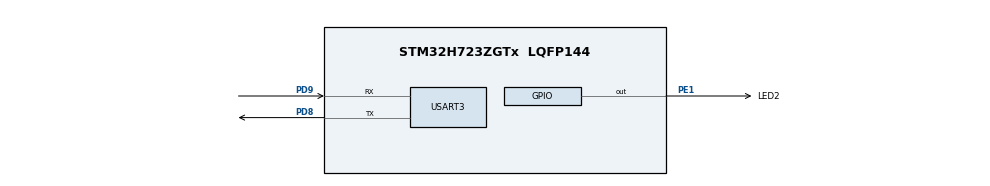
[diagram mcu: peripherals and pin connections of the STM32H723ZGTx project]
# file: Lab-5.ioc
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ADC3.Channel-0\#ChannelRegularConversion=ADC_CHANNEL_TEMPSENSOR
ADC3.NbrOfConversionFlag=1
ADC3.OffsetNumber-0\#ChannelRegularConversion=ADC_OFFSET_NONE
ADC3.OffsetSign-0\#ChannelRegularConversion=ADC3_OFFSET_SIGN_NEGATIVE
ADC3.Rank-0\#ChannelRegularConversion=1
ADC3.SamplingTime-0\#ChannelRegularConversion=ADC3_SAMPLETIME_2CYCLES_5
CORTEX_M7.default_mode_Activation=1
Mcu.Family=STM32H7
Mcu.Name=STM32H723ZGTx
Mcu.Package=LQFP144
NVIC.PriorityGroup=NVIC_PRIORITYGROUP_4
PA13(JTMS/SWDIO).Signal=DEBUG_JTMS-SWDIO
PA14(JTCK/SWCLK).Signal=DEBUG_JTCK-SWCLK
PC14-OSC32_IN.Mode=LSE-External-Oscillator
PC14-OSC32_IN.Signal=RCC_OSC32_IN
PC15-OSC32_OUT.Mode=LSE-External-Oscillator
PC15-OSC32_OUT.Signal=RCC_OSC32_OUT
PD8.Mode=Asynchronous
PD8.Signal=USART3_TX
PD9.Mode=Asynchronous
PD9.Signal=USART3_RX
PE1.GPIO_Label=LED2
PE1.Signal=GPIO_Output
ProjectManager.HeapSize=0x200
ProjectManager.StackSize=0x400
ProjectManager.TargetToolchain=Makefile
RCC.ADCFreq_Value=38400000
RCC.APB1Freq_Value=32000000
RCC.APB2Freq_Value=64000000
RCC.APB3Freq_Value=64000000
RCC.APB4Freq_Value=64000000
RCC.CortexFreq_Value=64000000
RCC.D2PPRE1=RCC_APB1_DIV2
RCC.DIVM2=4
RCC.DIVN2=12
RCC.DIVP2=5
RCC.HCLKFreq_Value=64000000
RCC.PLL2FRACN=0
RCC.SYSCLKFreq_VALUE=64000000
RCC.USBFreq_Value=129000000
USART3.VirtualMode-Asynchronous=VM_ASYNC
VP_ADC3_TempSens_Input.Mode=IN-TempSens
VP_MEMORYMAP_VS_MEMORYMAP.Mode=CurAppReg
board=custom

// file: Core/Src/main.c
/* USER CODE BEGIN Header */
/**
  ******************************************************************************
  * @file           : main.c
  * @brief          : Main program body
  ******************************************************************************
  * @attention
  *
  * Copyright (c) 2025 STMicroelectronics.
  * All rights reserved.
  *
  * This software is licensed under terms that can be found in the LICENSE file
  * in the root directory of this software component.
  * If no LICENSE file comes with this software, it is provided AS-IS.
  *
  ******************************************************************************
  */
/* USER CODE END Header */
#include "main.h"

/* USER CODE BEGIN Includes */
#include <string.h>

/* USER CODE END Includes */

/* USER CODE BEGIN PD */
#define ADC_BUFF_LEN 4096

/* USER CODE END PD */

ADC_HandleTypeDef hadc3;

UART_HandleTypeDef huart3;

void SystemClock_Config(void);
static void MPU_Config(void);
static void MX_GPIO_Init(void);
static void MX_USART3_UART_Init(void);
static void MX_ADC3_Init(void);

/* USER CODE BEGIN 0 */
char buffer[100];
void _LOG_write_raw(char *txt);
uint16_t adc_buff[ADC_BUFF_LEN];

uint16_t get_ADC(){

  HAL_ADC_Start(&hadc3);
  HAL_ADC_PollForConversion(&hadc3, 1000);
  uint16_t value = HAL_ADC_GetValue(&hadc3);

  HAL_ADC_Stop(&hadc3);

  return value;
}

float convert_temp(uint16_t d_adc){

  float v_adc = d_adc * (3.3 / 4095.0);
  float temp = ((v_adc - 0.78 / 2.5));

  return temp;
}

/* USER CODE END 0 */

int main(void)
{

  /* MPU Configuration--------------------------------------------------------*/
  MPU_Config();

  /* MCU Configuration--------------------------------------------------------*/

  /* Reset of all peripherals, Initializes the Flash interface and the Systick. */
  HAL_Init();

  /* Configure the system clock */
  SystemClock_Config();

  /* Initialize all configured peripherals */
  MX_GPIO_Init();
  MX_USART3_UART_Init();
  MX_ADC3_Init();
  /* USER CODE BEGIN 2 */

  uint32_t t0;
  t0 = HAL_GetTick();
  uint16_t temp_adc = 0;

  /* USER CODE END 2 */

  /* Infinite loop */
  while (1)
  {
    if(HAL_GetTick() - t0 > 5000){

      uint16_t tmp = get_ADC();
      temp_adc = convert_temp(tmp);

      snprintf(buffer, sizeof(buffer), "Temperatire: %hu")
      _LOG_write_raw(buffer);
      t0 = HAL_GetTick();
    }

  }
}

void SystemClock_Config(void)
{
  RCC_OscInitTypeDef RCC_OscInitStruct = {0};
  RCC_ClkInitTypeDef RCC_ClkInitStruct = {0};

  /** Supply configuration update enable
  */
  HAL_PWREx_ConfigSupply(PWR_LDO_SUPPLY);

  /** Configure the main internal regulator output voltage
  */
  __HAL_PWR_VOLTAGESCALING_CONFIG(PWR_REGULATOR_VOLTAGE_SCALE3);

  while(!__HAL_PWR_GET_FLAG(PWR_FLAG_VOSRDY)) {}

  /** Macro to configure the PLL clock source
  */
  __HAL_RCC_PLL_PLLSOURCE_CONFIG(RCC_PLLSOURCE_HSI);

  /** Initializes the RCC Oscillators according to the specified parameters
  * in the RCC_OscInitTypeDef structure.
  */
  RCC_OscInitStruct.OscillatorType = RCC_OSCILLATORTYPE_HSI;
  RCC_OscInitStruct.HSIState = RCC_HSI_DIV1;
  RCC_OscInitStruct.HSICalibrationValue = 64;
  RCC_OscInitStruct.PLL.PLLState = RCC_PLL_NONE;
  if (HAL_RCC_OscConfig(&RCC_OscInitStruct) != HAL_OK)
  {
    Error_Handler();
  }

  /** Initializes the CPU, AHB and APB buses clocks
  */
  RCC_ClkInitStruct.ClockType = RCC_CLOCKTYPE_HCLK|RCC_CLOCKTYPE_SYSCLK
                              |RCC_CLOCKTYPE_PCLK1|RCC_CLOCKTYPE_PCLK2
                              |RCC_CLOCKTYPE_D3PCLK1|RCC_CLOCKTYPE_D1PCLK1;
  RCC_ClkInitStruct.SYSCLKSource = RCC_SYSCLKSOURCE_HSI;
  RCC_ClkInitStruct.SYSCLKDivider = RCC_SYSCLK_DIV1;
  RCC_ClkInitStruct.AHBCLKDivider = RCC_HCLK_DIV1;
  RCC_ClkInitStruct.APB3CLKDivider = RCC_APB3_DIV1;
  RCC_ClkInitStruct.APB1CLKDivider = RCC_APB1_DIV2;
  RCC_ClkInitStruct.APB2CLKDivider = RCC_APB2_DIV1;
  RCC_ClkInitStruct.APB4CLKDivider = RCC_APB4_DIV1;

  if (HAL_RCC_ClockConfig(&RCC_ClkInitStruct, FLASH_LATENCY_1) != HAL_OK)
  {
    Error_Handler();
  }
}

static void MX_ADC3_Init(void)
{

  ADC_ChannelConfTypeDef sConfig = {0};

  /** Common config
  */
  hadc3.Instance = ADC3;
  hadc3.Init.ClockPrescaler = ADC_CLOCK_ASYNC_DIV1;
  hadc3.Init.Resolution = ADC_RESOLUTION_12B;
  hadc3.Init.DataAlign = ADC3_DATAALIGN_RIGHT;
  hadc3.Init.ScanConvMode = ADC_SCAN_DISABLE;
  hadc3.Init.EOCSelection = ADC_EOC_SINGLE_CONV;
  hadc3.Init.LowPowerAutoWait = DISABLE;
  hadc3.Init.ContinuousConvMode = DISABLE;
  hadc3.Init.NbrOfConversion = 1;
  hadc3.Init.DiscontinuousConvMode = DISABLE;
  hadc3.Init.ExternalTrigConv = ADC_SOFTWARE_START;
  hadc3.Init.ExternalTrigConvEdge = ADC_EXTERNALTRIGCONVEDGE_NONE;
  hadc3.Init.DMAContinuousRequests = DISABLE;
  hadc3.Init.SamplingMode = ADC_SAMPLING_MODE_NORMAL;
  hadc3.Init.ConversionDataManagement = ADC_CONVERSIONDATA_DR;
  hadc3.Init.Overrun = ADC_OVR_DATA_PRESERVED;
  hadc3.Init.LeftBitShift = ADC_LEFTBITSHIFT_NONE;
  hadc3.Init.OversamplingMode = DISABLE;
  hadc3.Init.Oversampling.Ratio = ADC3_OVERSAMPLING_RATIO_2;
  if (HAL_ADC_Init(&hadc3) != HAL_OK)
  {
    Error_Handler();
  }

  /** Configure Regular Channel
  */
  sConfig.Channel = ADC_CHANNEL_TEMPSENSOR;
  sConfig.Rank = ADC_REGULAR_RANK_1;
  sConfig.SamplingTime = ADC3_SAMPLETIME_2CYCLES_5;
  sConfig.SingleDiff = ADC_SINGLE_ENDED;
  sConfig.OffsetNumber = ADC_OFFSET_NONE;
  sConfig.Offset = 0;
  sConfig.OffsetSign = ADC3_OFFSET_SIGN_NEGATIVE;
  if (HAL_ADC_ConfigChannel(&hadc3, &sConfig) != HAL_OK)
  {
    Error_Handler();
  }

}

static void MX_USART3_UART_Init(void)
{

  huart3.Instance = USART3;
  huart3.Init.BaudRate = 115200;
  huart3.Init.WordLength = UART_WORDLENGTH_8B;
  huart3.Init.StopBits = UART_STOPBITS_1;
  huart3.Init.Parity = UART_PARITY_NONE;
  huart3.Init.Mode = UART_MODE_TX_RX;
  huart3.Init.HwFlowCtl = UART_HWCONTROL_NONE;
  huart3.Init.OverSampling = UART_OVERSAMPLING_16;
  huart3.Init.OneBitSampling = UART_ONE_BIT_SAMPLE_DISABLE;
  huart3.Init.ClockPrescaler = UART_PRESCALER_DIV1;
  huart3.AdvancedInit.AdvFeatureInit = UART_ADVFEATURE_NO_INIT;
  if (HAL_UART_Init(&huart3) != HAL_OK)
  {
    Error_Handler();
  }
  if (HAL_UARTEx_SetTxFifoThreshold(&huart3, UART_TXFIFO_THRESHOLD_1_8) != HAL_OK)
  {
    Error_Handler();
  }
  if (HAL_UARTEx_SetRxFifoThreshold(&huart3, UART_RXFIFO_THRESHOLD_1_8) != HAL_OK)
  {
    Error_Handler();
  }
  if (HAL_UARTEx_DisableFifoMode(&huart3) != HAL_OK)
  {
    Error_Handler();
  }

}

static void MX_GPIO_Init(void)
{
  GPIO_InitTypeDef GPIO_InitStruct = {0};

  /* GPIO Ports Clock Enable */
  __HAL_RCC_GPIOC_CLK_ENABLE();
  __HAL_RCC_GPIOD_CLK_ENABLE();
  __HAL_RCC_GPIOA_CLK_ENABLE();
  __HAL_RCC_GPIOE_CLK_ENABLE();

  /*Configure GPIO pin Output Level */
  HAL_GPIO_WritePin(LED2_GPIO_Port, LED2_Pin, GPIO_PIN_RESET);

  /*Configure GPIO pin : LED2_Pin */
  GPIO_InitStruct.Pin = LED2_Pin;
  GPIO_InitStruct.Mode = GPIO_MODE_OUTPUT_PP;
  GPIO_InitStruct.Pull = GPIO_NOPULL;
  GPIO_InitStruct.Speed = GPIO_SPEED_FREQ_LOW;
  HAL_GPIO_Init(LED2_GPIO_Port, &GPIO_InitStruct);

}

/* USER CODE BEGIN 4 */

void _LOG_write_raw(char *txt) {
    HAL_UART_Transmit(&huart3, (uint8_t*)txt, sizeof(txt), 10);
    // HAL_UART_Transmit(&huart1, (uint8_t*)"\033[K\r\n", 5, 10);
}

/* USER CODE END 4 */

 /* MPU Configuration */

void MPU_Config(void)
{
  MPU_Region_InitTypeDef MPU_InitStruct = {0};

  /* Disables the MPU */
  HAL_MPU_Disable();

  /** Initializes and configures the Region and the memory to be protected
  */
  MPU_InitStruct.Enable = MPU_REGION_ENABLE;
  MPU_InitStruct.Number = MPU_REGION_NUMBER0;
  MPU_InitStruct.BaseAddress = 0x0;
  MPU_InitStruct.Size = MPU_REGION_SIZE_4GB;
  MPU_InitStruct.SubRegionDisable = 0x87;
  MPU_InitStruct.TypeExtField = MPU_TEX_LEVEL0;
  MPU_InitStruct.AccessPermission = MPU_REGION_NO_ACCESS;
  MPU_InitStruct.DisableExec = MPU_INSTRUCTION_ACCESS_DISABLE;
  MPU_InitStruct.IsShareable = MPU_ACCESS_SHAREABLE;
  MPU_InitStruct.IsCacheable = MPU_ACCESS_NOT_CACHEABLE;
  MPU_InitStruct.IsBufferable = MPU_ACCESS_NOT_BUFFERABLE;

  HAL_MPU_ConfigRegion(&MPU_InitStruct);
  /* Enables the MPU */
  HAL_MPU_Enable(MPU_PRIVILEGED_DEFAULT);

}

void Error_Handler(void)
{
  __disable_irq();
  while (1)
  {
  }
}
